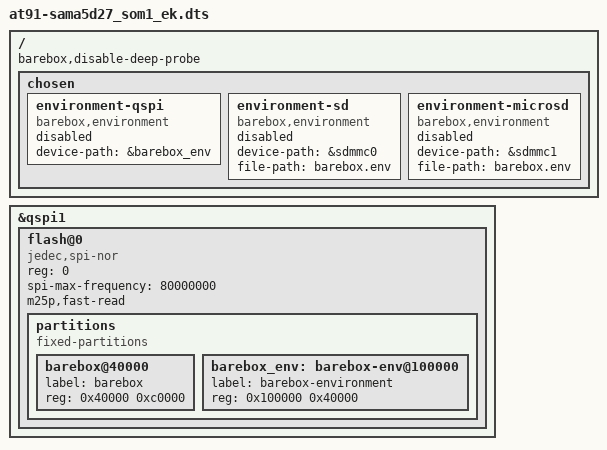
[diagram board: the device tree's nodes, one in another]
// SPDX-License-Identifier: GPL-2.0 OR X11
/*
 * Copyright (C) 2019 Oleksij Rempel - Pengutronix
 */

#include <arm/microchip/at91-sama5d27_som1_ek.dts>
#include "at91-sama5d27_som1.dtsi"

/ {
	barebox,disable-deep-probe;

	chosen {
		environment-qspi {
			compatible = "barebox,environment";
			device-path = &barebox_env;
			status = "disabled";
		};

		environment-sd {
			compatible = "barebox,environment";
			device-path = &sdmmc0;
			file-path = "barebox.env";
			status = "disabled";
		};

		environment-microsd {
			compatible = "barebox,environment";
			device-path = &sdmmc1;
			file-path = "barebox.env";
			status = "disabled";
		};
	};
};

/delete-node/ &{qspi1/flash@0};
&qspi1 {
	flash@0 {
		compatible = "jedec,spi-nor";
		reg = <0>;
		spi-max-frequency = <80000000>;
		m25p,fast-read;

		partitions {
			compatible = "fixed-partitions";
			#address-cells = <1>;
			#size-cells = <1>;

			barebox@40000 {
				label = "barebox";
				reg = <0x40000 0xc0000>;
			};

			barebox_env: barebox-env@100000 {
				label = "barebox-environment";
				reg = <0x100000 0x40000>;
			};
		};
	};
};
